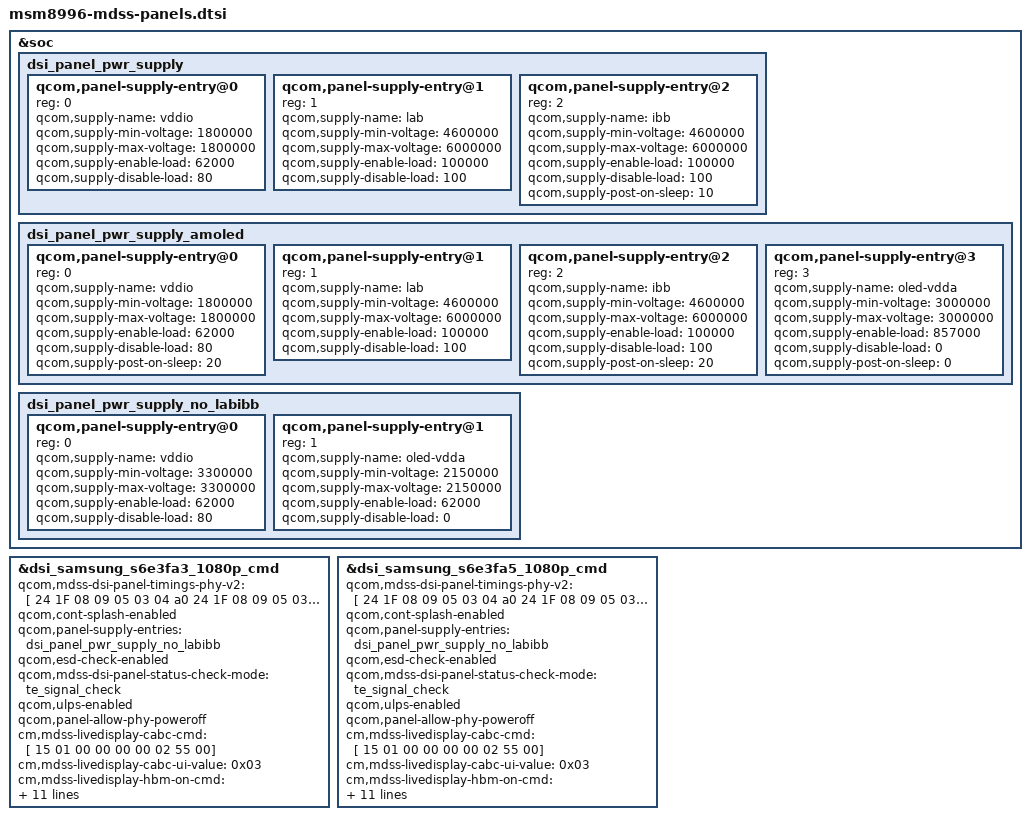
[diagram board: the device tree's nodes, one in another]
/* Copyright (c) 2015-2017, The Linux Foundation. All rights reserved.
 *
 * This program is free software; you can redistribute it and/or modify
 * it under the terms of the GNU General Public License version 2 and
 * only version 2 as published by the Free Software Foundation.
 *
 * This program is distributed in the hope that it will be useful,
 * but WITHOUT ANY WARRANTY; without even the implied warranty of
 * MERCHANTABILITY or FITNESS FOR A PARTICULAR PURPOSE.  See the
 * GNU General Public License for more details.
 */

#include "dsi-panel-samsung_s6e3fa3_1080p_cmd.dtsi"  //guozhiming modify for lcd 2015-10-15
#include "dsi-panel-samsung_s6e3fa5_1080p_cmd.dtsi"

&soc {
	dsi_panel_pwr_supply: dsi_panel_pwr_supply {
		#address-cells = <1>;
		#size-cells = <0>;

		qcom,panel-supply-entry@0 {
			reg = <0>;
			qcom,supply-name = "vddio";
			qcom,supply-min-voltage = <1800000>;
			qcom,supply-max-voltage = <1800000>;
			qcom,supply-enable-load = <62000>;
			qcom,supply-disable-load = <80>;
		};

		qcom,panel-supply-entry@1 {
			reg = <1>;
			qcom,supply-name = "lab";
			qcom,supply-min-voltage = <4600000>;
			qcom,supply-max-voltage = <6000000>;
			qcom,supply-enable-load = <100000>;
			qcom,supply-disable-load = <100>;
		};

		qcom,panel-supply-entry@2 {
			reg = <2>;
			qcom,supply-name = "ibb";
			qcom,supply-min-voltage = <4600000>;
			qcom,supply-max-voltage = <6000000>;
			qcom,supply-enable-load = <100000>;
			qcom,supply-disable-load = <100>;
			qcom,supply-post-on-sleep = <10>;
		};
	};
};

&soc {
	dsi_panel_pwr_supply_amoled: dsi_panel_pwr_supply_amoled {
		#address-cells = <1>;
		#size-cells = <0>;

		qcom,panel-supply-entry@0 {
			reg = <0>;
			qcom,supply-name = "vddio";
			qcom,supply-min-voltage = <1800000>;
			qcom,supply-max-voltage = <1800000>;
			qcom,supply-enable-load = <62000>;
			qcom,supply-disable-load = <80>;
			qcom,supply-post-on-sleep = <20>;
		};

		qcom,panel-supply-entry@1 {
			reg = <1>;
			qcom,supply-name = "lab";
			qcom,supply-min-voltage = <4600000>;
			qcom,supply-max-voltage = <6000000>;
			qcom,supply-enable-load = <100000>;
			qcom,supply-disable-load = <100>;
		};

		qcom,panel-supply-entry@2 {
			reg = <2>;
			qcom,supply-name = "ibb";
			qcom,supply-min-voltage = <4600000>;
			qcom,supply-max-voltage = <6000000>;
			qcom,supply-enable-load = <100000>;
			qcom,supply-disable-load = <100>;
			qcom,supply-post-on-sleep = <20>;
		};

		qcom,panel-supply-entry@3 {
			reg = <3>;
			qcom,supply-name = "oled-vdda";
			qcom,supply-min-voltage = <3000000>;
			qcom,supply-max-voltage = <3000000>;
			qcom,supply-enable-load = <857000>;
			qcom,supply-disable-load = <0>;
			qcom,supply-post-on-sleep = <0>;
		};
	};
};

&soc {
	dsi_panel_pwr_supply_no_labibb: dsi_panel_pwr_supply_no_labibb {
		#address-cells = <1>;
		#size-cells = <0>;

		qcom,panel-supply-entry@0 {
			reg = <0>;
			qcom,supply-name = "vddio";
			//qcom,supply-min-voltage = <1800000>; //guozhiming modify for lcd 2015-10-15
			//qcom,supply-max-voltage = <1800000>;
			qcom,supply-min-voltage = <3300000>;
			qcom,supply-max-voltage = <3300000>;
			qcom,supply-enable-load = <62000>;
			qcom,supply-disable-load = <80>;
			//qcom,supply-post-on-sleep = <20>; yankelong del，don't need in 15801
		};

		qcom,panel-supply-entry@1 {
			reg = <1>;
			qcom,supply-name = "oled-vdda";
			qcom,supply-min-voltage = <2150000>;
			qcom,supply-max-voltage = <2150000>;
			qcom,supply-enable-load = <62000>;
			qcom,supply-disable-load = <0>;
		};
	};
};
//guozhiming modify for lcd 2015-10-15
&dsi_samsung_s6e3fa3_1080p_cmd {
	qcom,mdss-dsi-panel-timings-phy-v2 = [
       24 1F 08 09 05 03 04 a0
       24 1F 08 09 05 03 04 a0
       24 1F 08 09 05 03 04 a0
       24 1F 08 09 05 03 04 a0
       24 1B 08 09 05 03 04 a0];
	qcom,cont-splash-enabled;
	qcom,panel-supply-entries = <&dsi_panel_pwr_supply_no_labibb>;
	qcom,esd-check-enabled;
	qcom,mdss-dsi-panel-status-check-mode = "te_signal_check";
	qcom,ulps-enabled;
	qcom,panel-allow-phy-poweroff;
	cm,mdss-livedisplay-cabc-cmd = [
		15 01 00 00 00 00 02 55 00];
	cm,mdss-livedisplay-cabc-ui-value = <0x03>;
	cm,mdss-livedisplay-hbm-on-cmd = [
		15 01 00 00 00 00 02 53 E0];
	cm,mdss-livedisplay-hbm-off-cmd = [
		15 01 00 00 00 00 02 53 20];
	cm,mdss-livedisplay-srgb-on-cmd = [
		39 01 00 00 00 00 03 F0 5A 5A
		39 01 00 00 00 00 02 57 A4
		39 01 00 00 00 00 02 B0 32
		39 01 00 00 00 00 16 ED B8 03 04 45 E2 10 04 07 C1 4B EB D7 B8 0A BF FF ED 14 F7 f2 D7
		39 01 00 00 00 00 03 F0 A5 A5];
	cm,mdss-livedisplay-srgb-off-cmd = [
		39 01 00 00 00 00 03 F0 5A 5A
		39 01 00 00 00 00 02 57 40
		39 01 00 00 00 00 03 F0 A5 A5];
	cm,mdss-livedisplay-dci-p3-on-cmd = [
		39 01 00 00 00 00 03 F0 5A 5A
		39 01 00 00 00 00 02 57 A4
		39 01 00 00 00 00 02 B0 32
		39 01 00 00 00 00 16 ED D8 00 00 16 D2 00 08 08 C3 1C F1 CF E8 02 C8 E9 DF 00 FF F6 D7
		39 01 00 00 00 00 03 f0 A5 A5];
	cm,mdss-livedisplay-dci-p3-off-cmd = [
		39 01 00 00 00 00 03 F0 5A 5A
		39 01 00 00 00 00 02 57 40
		39 01 00 00 00 00 03 F0 A5 A5];
};

&dsi_samsung_s6e3fa5_1080p_cmd {
       qcom,mdss-dsi-panel-timings-phy-v2 = [
       24 1F 08 09 05 03 04 a0
       24 1F 08 09 05 03 04 a0
       24 1F 08 09 05 03 04 a0
       24 1F 08 09 05 03 04 a0
       24 1B 08 09 05 03 04 a0];
	qcom,cont-splash-enabled;
	qcom,panel-supply-entries = <&dsi_panel_pwr_supply_no_labibb>;
	qcom,esd-check-enabled;
	qcom,mdss-dsi-panel-status-check-mode = "te_signal_check";
	qcom,ulps-enabled;
	qcom,panel-allow-phy-poweroff;
	cm,mdss-livedisplay-cabc-cmd = [
		15 01 00 00 00 00 02 55 00];
	cm,mdss-livedisplay-cabc-ui-value = <0x03>;
	cm,mdss-livedisplay-hbm-on-cmd = [
		15 01 00 00 00 00 02 53 E0];
	cm,mdss-livedisplay-hbm-off-cmd = [
		15 01 00 00 00 00 02 53 20];
	cm,mdss-livedisplay-srgb-on-cmd = [
		39 01 00 00 00 00 03 f0 5a 5a
		39 01 00 00 00 00 02 C3 81
		39 01 00 00 00 00 02 B0 19
		39 01 00 00 00 00 16 C3 C9 00 04 49 EF 16 04 07 CF 44 DB D9 A1 06 C0 F2 EA 1B F7 f2 D7
		39 01 00 00 00 00 02 B0 18
		39 01 00 00 00 00 02 C3 01
		39 01 00 00 00 00 03 f0 A5 A5];
	cm,mdss-livedisplay-srgb-off-cmd = [
		39 01 00 00 00 00 03 F0 5A 5A
		39 01 00 00 00 00 02 C3 01
		39 01 00 00 00 00 02 B0 18
		39 01 00 00 00 00 02 C3 00
		39 01 00 00 00 00 03 F0 A5 A5];
	cm,mdss-livedisplay-dci-p3-on-cmd = [
		39 01 00 00 00 00 03 f0 5A 5A
		39 01 00 00 00 00 02 C3 81
		39 01 00 00 00 00 02 B0 19
		39 01 00 00 00 00 16 C3 D8 00 00 16 D2 00 08 08 C3 1C F1 CF E8 02 C8 E9 DF 00 FF F6 D7
		39 01 00 00 00 00 02 B0 18
		39 01 00 00 00 00 02 C3 01
		39 01 00 00 00 00 03 f0 A5 A5];
	cm,mdss-livedisplay-dci-p3-off-cmd = [
		39 01 00 00 00 00 03 F0 5A 5A
		39 01 00 00 00 00 02 C3 01
		39 01 00 00 00 00 02 B0 18
		39 01 00 00 00 00 02 C3 00
		39 01 00 00 00 00 03 F0 A5 A5];
};
